# ATtiny26 device description
Architecture: AVR8; Family: tinyAVR
Programming and debug interfaces: ISP, HVPP
Registers are 8-bit, access not given, no defined reset value unless marked. A register's access mark holds for its fields unless they carry their own. Offsets are from the block's base; lines under a group give offsets from that group; [hi:lo] are bit positions; {n}, {i} and the like mark numbered series; 'fields as' and 'values as' point back to an identical list; <NAME> marks a mode.

## Ordering variants
standard: 2.7 to 5.5 V

## Memory
prog space: start 0x0000 size 0x0800, little endian
  0x0000 FLASH size 0x0800 flash, rw, executable, page 0x20
signatures space: start 0 size 3, little endian
  0 SIGNATURES size 3 signatures, ro
fuses space: start 0 size 0x0002, little endian
  0 FUSES size 0x0002 fuses, rw
lockbits space: start 0 size 0x0001, little endian
  0 LOCKBITS size 0x0001 lockbits, rw
data space: start 0x0000 size 0x00e0, little endian
  0x0000 REGISTERS size 0x0020 regs
  0x0020 MAPPED_IO size 0x0040 io
  0x0060 IRAM size 0x0080 ram
eeprom space: start 0x0000 size 0x0080, little endian
  0x0000 EEPROM size 0x0080 eeprom, rw, page 0x04
io space: start 0x00 size 0x40, little endian
osccal space: start 0 size 4, little endian
  0 OSCCAL size 4 osccal, ro

## Peripheral instances (address, pins/pin function, parameters)
ADC at 0x00 — Analog-to-Digital Converter
AC at 0x00 — Analog Comparator
USI at 0x00 — Universal Serial Interface
PORTA at 0x00 — I/O Port
PORTB at 0x00 — I/O Port
EEPROM at 0x00
WDT at 0x00 — Watchdog Timer
CPU at 0x00 — CPU Registers
TC0 at 0x00 — Timer/Counter, 8-bit
TC1 at 0x00 — Timer/Counter, 8-bit
EXINT at 0x00 — External Interrupts
FUSE at 0 in fuses — Fuses
LOCKBIT at 0 in lockbits — Lockbits

## Interrupts
0 RESET — External Reset, Power-on Reset and Watchdog Reset
1 INT0 — External Interrupt 0
2 IO_PINS — External Interrupt Request 0
3 TIMER1_CMPA — Timer/Counter1 Compare Match 1A
4 TIMER1_CMPB — Timer/Counter1 Compare Match 1B
5 TIMER1_OVF1 — Timer/Counter1 Overflow
6 TIMER0_OVF0 — Timer/Counter0 Overflow
7 USI_STRT — USI Start
8 USI_OVF — USI Overflow
9 EE_RDY — EEPROM Ready
10 ANA_COMP — Analog Comparator
11 ADC — ADC Conversion Complete

## Properties
SIGNATURES: SIGNATURE0=0x1e, SIGNATURE1=0x91, SIGNATURE2=0x09

## LOCKBIT — Lockbits
Instances: LOCKBIT 0 in lockbits
0x00 LOCKBIT
  [1:0] LB — Memory Lock
    0=PROG_VER_DISABLED (Further programming and verification disabled); 2=PROG_DISABLED (Further programming disabled); 3=NO_LOCK (No memory lock features enabled)

## ADC — Analog-to-Digital Converter
Instances: ADC 0x00
0x24 ADC 16-bit — ADC Data Register Bytes
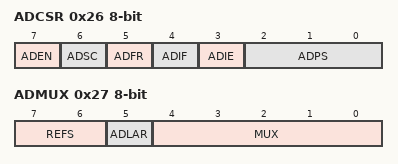
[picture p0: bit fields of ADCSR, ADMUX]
0x26 ADCSR — The ADC Control and Status register
  [7] ADEN — ADC Enable
  [6] ADSC — ADC Start Conversion
  [5] ADFR — ADC Free Running Select
  [4] ADIF — ADC Interrupt Flag
  [3] ADIE — ADC Interrupt Enable
  [2:0] ADPS — ADC Prescaler Select Bits
    0=2; 1=2; 2=4; 3=8; 4=16; 5=32; 6=64; 7=128
0x27 ADMUX — The ADC multiplexer Selection Register
  [7:6] REFS — Reference Selection Bits
    0=AVCC; 1=AREF; 2=Internal Voltage Referance; 3=Internal Voltage Reference With External Capacitor at AREF Pin
  [5] ADLAR — Left Adjust Result
  [4:0] MUX — Analog Channel and Gain Selection Bits

## AC — Analog Comparator
Instances: AC 0x00
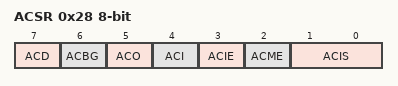
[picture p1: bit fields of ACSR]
0x28 ACSR — Analog Comparator Control And Status Register
  [7] ACD — Analog Comparator Disable
  [6] ACBG — Analog Comparator Bandgap Select
  [5] ACO — Analog Compare Output
  [4] ACI — Analog Comparator Interrupt Flag
  [3] ACIE — Analog Comparator Interrupt Enable
  [2] ACME — Analog Comparator Multiplexer Enable
  [1:0] ACIS — Analog Comparator Interrupt Mode Select bits
    0=Interrupt on Toggle; 2=Interrupt on Falling Edge; 3=Interrupt on Rising Edge

## USI — Universal Serial Interface
Instances: USI 0x00
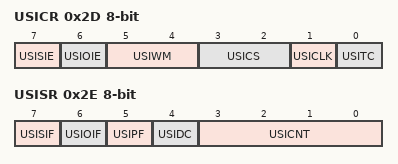
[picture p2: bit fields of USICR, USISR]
0x2D USICR — USI Control Register
  [7] USISIE — Start Condition Interrupt Enable
  [6] USIOIE — Counter Overflow Interrupt Enable
  [5:4] USIWM — USI Wire Mode Bits
    0=Normal Operation; 1=Three-Wire Mode; 2=Two-Wire Mode; 3=Two-Wire Mode Held Low
  [3:2] USICS — USI Clock Source Select Bits
  [1] USICLK — Clock Strobe
  [0] USITC — Toggle Clock Port Pin
0x2E USISR — USI Status Register
  [7] USISIF — Start Condition Interrupt Flag
  [6] USIOIF — Counter Overflow Interrupt Flag
  [5] USIPF — Stop Condition Flag
  [4] USIDC — Data Output Collision
  [3:0] USICNT — USI Counter Value Bits
0x2F USIDR — USI Data Register
